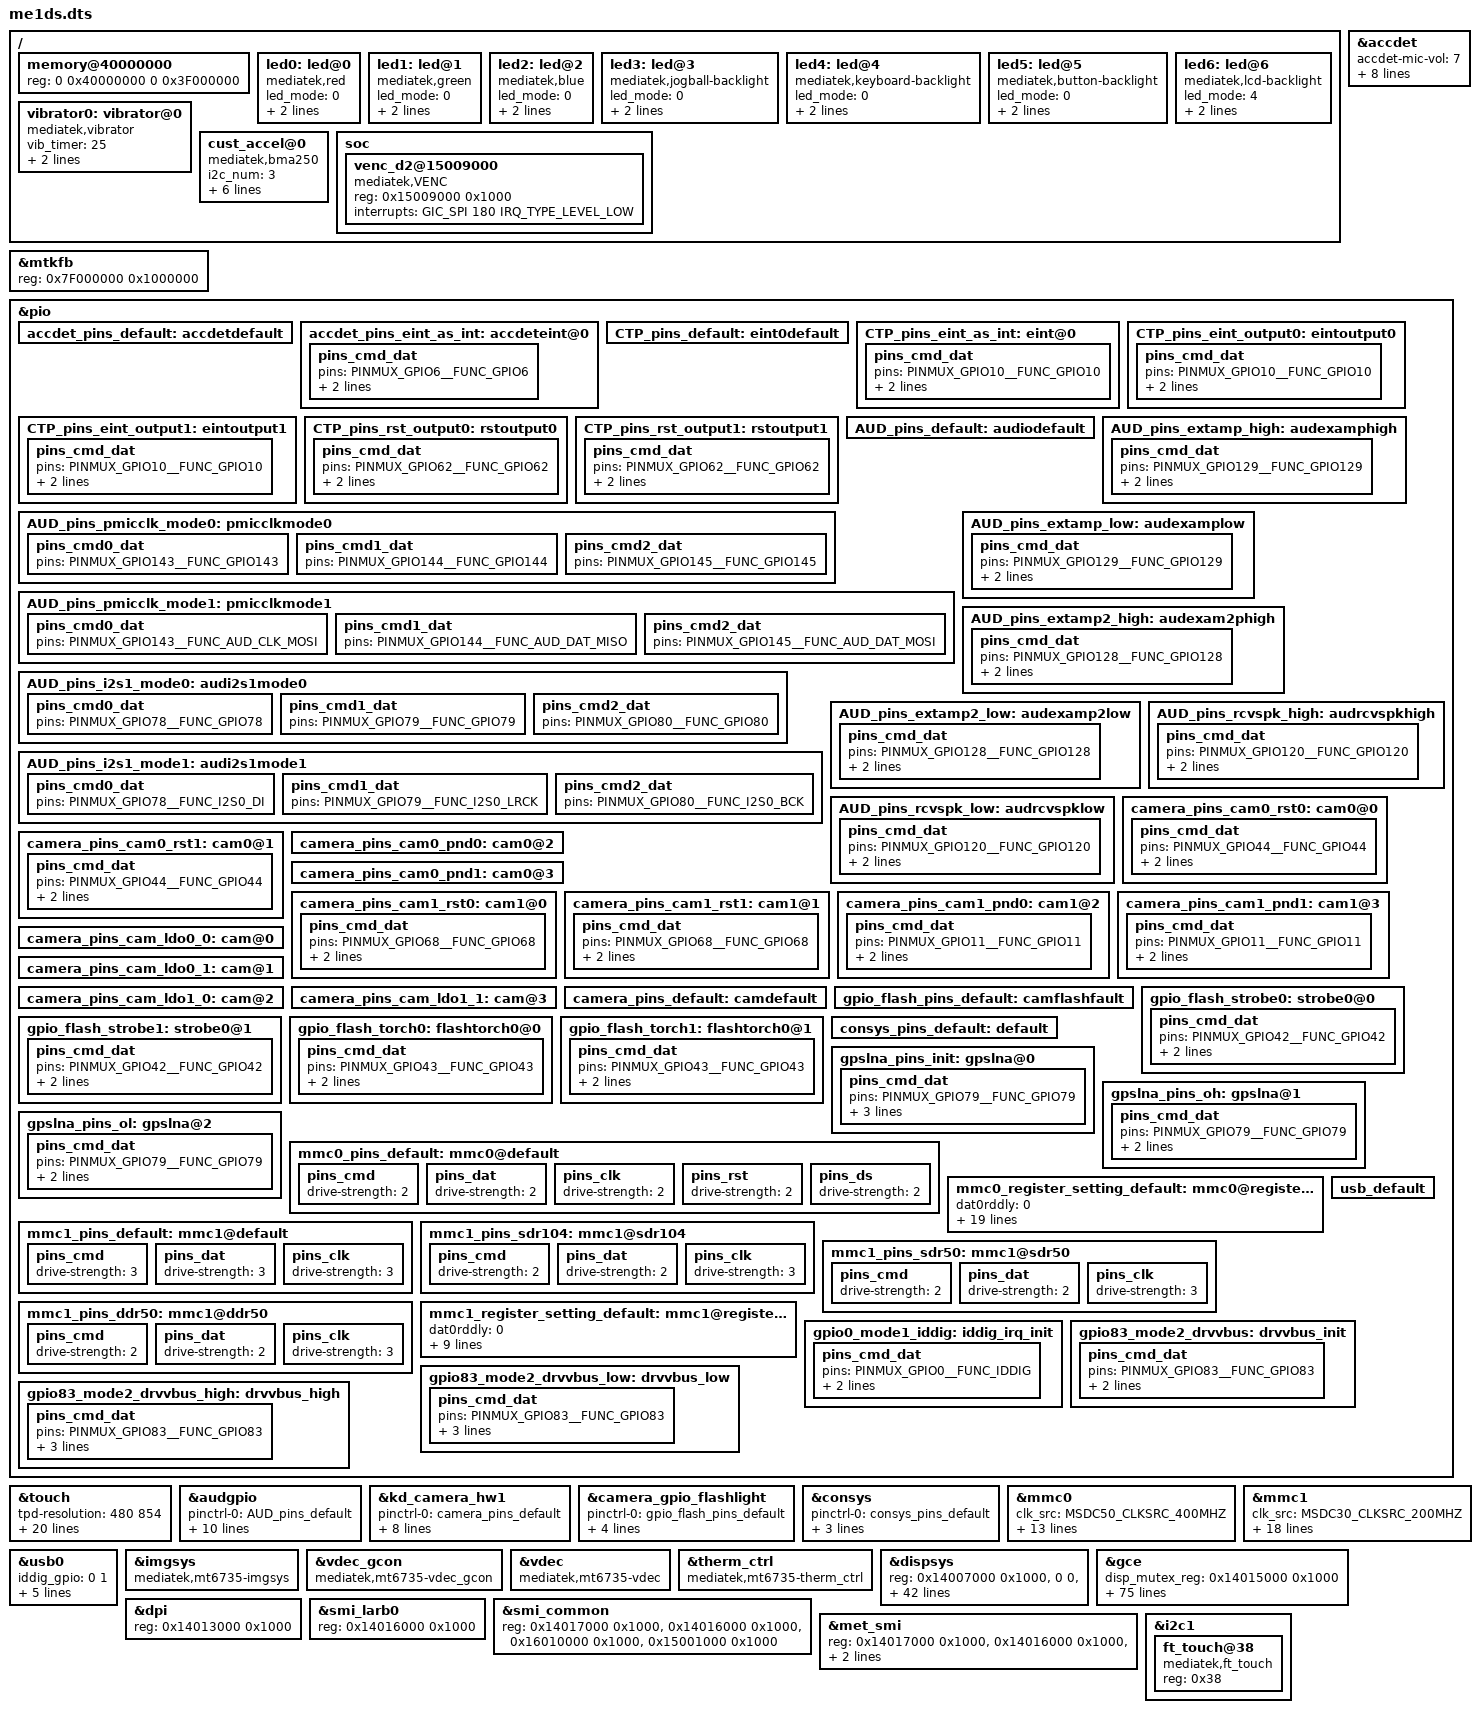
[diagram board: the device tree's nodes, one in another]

/dts-v1/;
/* LG K130 (me1ds, MT6735M), derived from the Coolpad CP8298_I00 board file */

#include "mt6735.dtsi"
#include "cust.dtsi"


/ {
	memory@40000000 {
		device_type = "memory";
		reg = <0 0x40000000 0 0x3F000000>;
	};

	led0:led@0 {
		compatible = "mediatek,red";
		led_mode = <0>;
		data = <1>;
		pwm_config = <0 0 0 0 0>;
	};
	led1:led@1 {
		compatible = "mediatek,green";
		led_mode = <0>;
		data = <2>;
		pwm_config = <0 0 0 0 0>;
	};
	led2:led@2 {
		compatible = "mediatek,blue";
		led_mode = <0>;
		data = <1>;
		pwm_config = <0 0 0 0 0>;
	};
	led3:led@3 {
		compatible = "mediatek,jogball-backlight";
		led_mode = <0>;
		data = <1>;
		pwm_config = <0 0 0 0 0>;
	};
	led4:led@4 {
		compatible = "mediatek,keyboard-backlight";
		led_mode = <0>;
		data = <1>;
		pwm_config = <0 0 0 0 0>;
	};
	led5:led@5 {
		compatible = "mediatek,button-backlight";
		led_mode = <0>;
		data = <1>;
		pwm_config = <0 0 0 0 0>;
	};
	led6:led@6 {
		compatible = "mediatek,lcd-backlight";
		led_mode = <4>;
		data = <1>;
		pwm_config = <0 0 0 0 0>;
	};
	vibrator0:vibrator@0 {
		compatible = "mediatek,vibrator";
		vib_timer = <25>;
		vib_limit = <9>;
		vib_vol= <5>;
	};



 /* sensor standardization */
		cust_accel@0 {
		compatible = "mediatek,bma250";
		i2c_num	= <3>;
		i2c_addr = <0x10 0 0 0>;
		direction = <5>;
		power_id = <0xffff>;
		power_vol = <0>;
		firlen = <0>;
		is_batch_supported = <0>;
		};








};


&mtkfb {
	reg = <0x7F000000 0x1000000>;
};




&accdet {
		accdet-mic-vol = <7>;
		headset-mode-setting = <0x500 0x200 1 0x1F0 0x800 0x800 0x20>;
		accdet-plugout-debounce = <20>;
		/*1:ACC mode, 2:low cost without in bias, 6:low cost with in bias*/
		accdet-mic-mode = <6>;
		/*0--MD_MAX--UP_MAX--DW_MAX*/
		headset-three-key-threshold = <0 80 192 500>;
		/*0--MD_MAX--VOICE_MAX--UP_MAX--DW_MAX*/
		headset-four-key-threshold = <0 58 121 192 450>;
};
/* ACCDET GPIO start*/
&pio {
	accdet_pins_default: accdetdefault {
	};
	accdet_pins_eint_as_int: accdeteint@0 {
		pins_cmd_dat {
			pins = <PINMUX_GPIO6__FUNC_GPIO6>;
			slew-rate = <0>;
			bias-disable;
		};
	};
};

&accdet {
		accdet-mic-vol = <7>;
		headset-mode-setting = <0x500 0x500 1 0x1F0 0x800 0x800 0x20>;
		accdet-plugout-debounce = <20>;
		/*1:ACC mode, 2:low cost without in bias, 6:low cost with in bias*/
		accdet-mic-mode = <1>;
		/*0--MD_MAX--UP_MAX--DW_MAX*/
		headset-three-key-threshold = <0 80 192 500>;
		/*0--MD_MAX--VOICE_MAX--UP_MAX--DW_MAX*/
		headset-four-key-threshold = <0 58 121 192 450>;
		pinctrl-names = "default", "state_eint_as_int";
		pinctrl-0 = <&accdet_pins_default>;
		pinctrl-1 = <&accdet_pins_eint_as_int>;
		status = "okay";
};
/* ACCDET GPIO end */
&touch {
	tpd-resolution = <480 854>;
	use-tpd-button = <0>;
	tpd-key-num = <3>;
	tpd-key-local= <580 172 158 0>;
	tpd-key-dim-local = <60 850 50 30 180 850 50 30 300 850 50 30 420 850 50 30>;
	tpd-max-touch-num = <5>;
	tpd-filter-enable = <0>;
	tpd-filter-pixel-density = <124>;
	tpd-filter-custom-prameters = <0 0 0 0 0 0 0 0 0 0 0 0>;
	tpd-filter-custom-speed = <0 0 0>;
	pinctrl-names = "default", "state_eint_as_int", "state_eint_output0", "state_eint_output1",
		"state_rst_output0", "state_rst_output1";
	pinctrl-0 = <&CTP_pins_default>;
	pinctrl-1 = <&CTP_pins_eint_as_int>;
	pinctrl-2 = <&CTP_pins_eint_output0>;
	pinctrl-3 = <&CTP_pins_eint_output1>;
	pinctrl-4 = <&CTP_pins_rst_output0>;
	pinctrl-5 = <&CTP_pins_rst_output1>;
	interrupt-parent = <&eintc>;
	interrupts = <10 IRQ_TYPE_EDGE_FALLING>;
	debounce = <10 0>;
	status = "okay";
};
&pio {
	CTP_pins_default: eint0default {
	};
	CTP_pins_eint_as_int: eint@0 {
		pins_cmd_dat {
			pins = <PINMUX_GPIO10__FUNC_GPIO10>;
			slew-rate = <0>;
			bias-disable;
		};
	};
	CTP_pins_eint_output0: eintoutput0 {
		pins_cmd_dat {
			pins = <PINMUX_GPIO10__FUNC_GPIO10>;
			slew-rate = <1>;
			output-low;
		};
	};
	CTP_pins_eint_output1: eintoutput1 {
		pins_cmd_dat {
			pins = <PINMUX_GPIO10__FUNC_GPIO10>;
			slew-rate = <1>;
			output-high;
		};
	};
	CTP_pins_rst_output0: rstoutput0 {
		pins_cmd_dat {
			pins = <PINMUX_GPIO62__FUNC_GPIO62>;
			slew-rate = <1>;
			output-low;
		};
	};
	CTP_pins_rst_output1: rstoutput1 {
		pins_cmd_dat {
			pins = <PINMUX_GPIO62__FUNC_GPIO62>;
			slew-rate = <1>;
			output-high;
		};
	};
};
/* TOUCH end */
/* AUDIO GPIO standardization */
&audgpio {
	pinctrl-names = "default", "audpmicclk-mode0", "audpmicclk-mode1", "audi2s1-mode0", "audi2s1-mode1", "extamp-pullhigh", "extamp-pulllow", "extamp2-pullhigh", "extamp2-pulllow", "rcvspk-pullhigh", "rcvspk-pulllow";
	pinctrl-0 = <&AUD_pins_default>;
	pinctrl-1 = <&AUD_pins_pmicclk_mode0>;
	pinctrl-2 = <&AUD_pins_pmicclk_mode1>;
	pinctrl-3 = <&AUD_pins_i2s1_mode0>;
	pinctrl-4 = <&AUD_pins_i2s1_mode1>;
	pinctrl-5 = <&AUD_pins_extamp_high>;
	pinctrl-6 = <&AUD_pins_extamp_low>;
	pinctrl-7 = <&AUD_pins_extamp2_high>;
	pinctrl-8 = <&AUD_pins_extamp2_low>;
	pinctrl-9 = <&AUD_pins_rcvspk_high>;
	pinctrl-10 = <&AUD_pins_rcvspk_low>;
	status = "okay";
};
&pio {
	AUD_pins_default: audiodefault {
	};
	AUD_pins_pmicclk_mode0: pmicclkmode0 {
		pins_cmd0_dat {
			pins = <PINMUX_GPIO143__FUNC_GPIO143>;
		};
		pins_cmd1_dat {
			pins = <PINMUX_GPIO144__FUNC_GPIO144>;
		};
		pins_cmd2_dat {
			pins = <PINMUX_GPIO145__FUNC_GPIO145>;
		};
	};
	AUD_pins_pmicclk_mode1: pmicclkmode1 {
		pins_cmd0_dat {
			pins = <PINMUX_GPIO143__FUNC_AUD_CLK_MOSI>;
		};
		pins_cmd1_dat {
			pins = <PINMUX_GPIO144__FUNC_AUD_DAT_MISO>;
		};
		pins_cmd2_dat {
			pins = <PINMUX_GPIO145__FUNC_AUD_DAT_MOSI>;
		};
	};
	AUD_pins_i2s1_mode0: audi2s1mode0 {
		pins_cmd0_dat {
			pins = <PINMUX_GPIO78__FUNC_GPIO78>;
		};
		pins_cmd1_dat {
			pins = <PINMUX_GPIO79__FUNC_GPIO79>;
		};
		pins_cmd2_dat {
			pins = <PINMUX_GPIO80__FUNC_GPIO80>;
		};
	};
	AUD_pins_i2s1_mode1: audi2s1mode1 {
		pins_cmd0_dat {
			pins = <PINMUX_GPIO78__FUNC_I2S0_DI>;
		};
		pins_cmd1_dat {
			pins = <PINMUX_GPIO79__FUNC_I2S0_LRCK>;
		};
		pins_cmd2_dat {
			pins = <PINMUX_GPIO80__FUNC_I2S0_BCK>;
		};
	};
	AUD_pins_extamp_high: audexamphigh {
		pins_cmd_dat {
			pins = <PINMUX_GPIO129__FUNC_GPIO129>;
				slew-rate = <1>;
				output-high;
		};
	};
	AUD_pins_extamp_low: audexamplow {
		pins_cmd_dat {
			pins = <PINMUX_GPIO129__FUNC_GPIO129>;
				slew-rate = <1>;
				output-low;
		};
	};
	AUD_pins_extamp2_high: audexam2phigh {
		pins_cmd_dat {
			pins = <PINMUX_GPIO128__FUNC_GPIO128>;
				slew-rate = <1>;
				output-high;
		};
	};
	AUD_pins_extamp2_low: audexamp2low {
		pins_cmd_dat {
			pins = <PINMUX_GPIO128__FUNC_GPIO128>;
				slew-rate = <1>;
				output-low;
		};
	};
	AUD_pins_rcvspk_high: audrcvspkhigh {
		pins_cmd_dat {
			pins = <PINMUX_GPIO120__FUNC_GPIO120>;
				slew-rate = <1>;
				output-high;
		};
	};
	AUD_pins_rcvspk_low: audrcvspklow {
		pins_cmd_dat {
			pins = <PINMUX_GPIO120__FUNC_GPIO120>;
				slew-rate = <1>;
				output-low;
		};
	};
};
/* AUDIO end */
/* CAMERA GPIO standardization */
&pio {
	camera_pins_cam0_rst0: cam0@0 {
		pins_cmd_dat {
			pins = <PINMUX_GPIO44__FUNC_GPIO44>;/*GPIO_CAMERA_CMRST_PIN*/
			slew-rate = <1>; /*direction 0:in, 1:out*/
			output-low;/*direction out used only. output_low or high*/
		};
	};
	camera_pins_cam0_rst1: cam0@1 {
		pins_cmd_dat {
			pins = <PINMUX_GPIO44__FUNC_GPIO44>;/*GPIO_CAMERA_CMRST_PIN*/
			slew-rate = <1>;
			output-high;
		};
	};
	camera_pins_cam0_pnd0: cam0@2 {
		/* not wired on the K130 */
	};
	camera_pins_cam0_pnd1: cam0@3 {
		/* not wired on the K130 */
	};
	camera_pins_cam1_rst0: cam1@0 {
		pins_cmd_dat {
			pins = <PINMUX_GPIO68__FUNC_GPIO68>;/*GPIO_CAMERA_CMRST1_PIN*/
			slew-rate = <1>; /*direction 0:in, 1:out*/
			output-low;/*direction out used only. output_low or high*/
		};
	};
	camera_pins_cam1_rst1: cam1@1 {
		pins_cmd_dat {
			pins = <PINMUX_GPIO68__FUNC_GPIO68>;/*GPIO_CAMERA_CMRST1_PIN*/
			slew-rate = <1>;
			output-high;
		};
	};
	camera_pins_cam1_pnd0: cam1@2 {
		pins_cmd_dat {
			pins = <PINMUX_GPIO11__FUNC_GPIO11>;/*GPIO_CAMERA_CMPDN1_PIN*/
			slew-rate = <1>;
			output-low;
		};
	};
	camera_pins_cam1_pnd1: cam1@3 {
		pins_cmd_dat {
			pins = <PINMUX_GPIO11__FUNC_GPIO11>;/*GPIO_CAMERA_CMPDN1_PIN*/
			slew-rate = <1>;
			output-high;
		};
	};
	camera_pins_cam_ldo0_0: cam@0 {
		/* not wired on the K130 */
	};
	camera_pins_cam_ldo0_1: cam@1 {
		/* not wired on the K130 */
	};
	camera_pins_cam_ldo1_0: cam@2 {
		/* not wired on the K130 */
	};
	camera_pins_cam_ldo1_1: cam@3 {
		/* not wired on the K130 */
	};
	camera_pins_default: camdefault {

	};
};

&kd_camera_hw1 {
	pinctrl-names = "default", "cam0_pnd0", "cam0_pnd1", "cam1_pnd0", "cam1_pnd1",
	"cam_ldo0_0", "cam_ldo0_1", "cam_ldo1_0", "cam_ldo1_1";
	pinctrl-0 = <&camera_pins_default>;
	pinctrl-1 = <&camera_pins_cam0_pnd0>;
	pinctrl-2 = <&camera_pins_cam0_pnd1>;
	pinctrl-3 = <&camera_pins_cam1_pnd0>;
	pinctrl-4= <&camera_pins_cam1_pnd1>;
	pinctrl-5 = <&camera_pins_cam_ldo0_0>;
	pinctrl-6 = <&camera_pins_cam_ldo0_1>;
	pinctrl-7 = <&camera_pins_cam_ldo1_0>;
	pinctrl-8 = <&camera_pins_cam_ldo1_1>;
	status = "okay";

};
/* CAMERA GPIO end */

/* CAMERA FLASH GPIO standardization */
&pio {
	gpio_flash_pins_default: camflashfault {
	};
	gpio_flash_strobe0: strobe0@0 {
		pins_cmd_dat {
			pins = <PINMUX_GPIO42__FUNC_GPIO42>;
			slew-rate = <1>;
			output-low;
		};
	};
	gpio_flash_strobe1: strobe0@1 {
		pins_cmd_dat {
			pins = <PINMUX_GPIO42__FUNC_GPIO42>;
			slew-rate = <1>;
			output-high;
		};
	};
	gpio_flash_torch0: flashtorch0@0 {
		pins_cmd_dat {
			pins = <PINMUX_GPIO43__FUNC_GPIO43>;
			slew-rate = <1>;
			output-low;
		};
	};
	gpio_flash_torch1: flashtorch0@1 {
		pins_cmd_dat {
			pins = <PINMUX_GPIO43__FUNC_GPIO43>;
			slew-rate = <1>;
			output-high;
		};
	};
};

&camera_gpio_flashlight {
	pinctrl-names = "default", "flash_strobe0", "flash_strobe1", "flash_torch0", "flash_torch1";
	pinctrl-0 = <&gpio_flash_pins_default>;
	pinctrl-1 = <&gpio_flash_strobe0>;
	pinctrl-2 = <&gpio_flash_strobe1>;
	pinctrl-3 = <&gpio_flash_torch0>;
	pinctrl-4 = <&gpio_flash_torch1>;
	status = "okay";
};
/* CAMERA FLASH GPIO end*/

/* CONSYS GPIO standardization */
&pio {
	consys_pins_default: default {

	};

	gpslna_pins_init: gpslna@0 {

	    pins_cmd_dat {
			pins = <PINMUX_GPIO79__FUNC_GPIO79>;
			slew-rate = <0>;
			bias-disable;
			output-low;
		};
	};

	gpslna_pins_oh: gpslna@1 {

	    pins_cmd_dat {
			pins = <PINMUX_GPIO79__FUNC_GPIO79>;
			slew-rate = <1>;
			output-high;
		};
	};

	gpslna_pins_ol: gpslna@2 {

	    pins_cmd_dat {
			pins = <PINMUX_GPIO79__FUNC_GPIO79>;
			slew-rate = <1>;
			output-low;
		};
	};

};

&consys {
	pinctrl-names = "default", "gps_lna_state_init", "gps_lna_state_oh", "gps_lna_state_ol";
	pinctrl-0 = <&consys_pins_default>;
	pinctrl-1 = <&gpslna_pins_init>;
	pinctrl-2 = <&gpslna_pins_oh>;
	pinctrl-3 = <&gpslna_pins_ol>;
	status = "okay";

};
/* CONSYS end */

/* mmc start */
&mmc0 {
		clk_src = /bits/ 8 <MSDC50_CLKSRC_400MHZ>;
		bus-width = <8>;
		max-frequency = <200000000>;
		cap-mmc-highspeed;
		msdc-sys-suspend;
		mmc-ddr-1_8v;
		mmc-hs200-1_8v;
		mmc-hs400-1_8v;
		non-removable;
		pinctl = <&mmc0_pins_default>;
		register_setting = <&mmc0_register_setting_default>;
		host_function = /bits/ 8 <MSDC_EMMC>;
		bootable;
		status = "okay";
};

&mmc1 {
		clk_src = /bits/ 8 <MSDC30_CLKSRC_200MHZ>;
		bus-width = <4>;
		max-frequency = <200000000>;
		msdc-sys-suspend;
		cap-sd-highspeed;
		sd-uhs-sdr12;
		sd-uhs-sdr25;
		sd-uhs-sdr50;
		sd-uhs-sdr104;
		sd-uhs-ddr50;
		pinctl = <&mmc1_pins_default>;
		pinctl_sdr104 = <&mmc1_pins_sdr104>;
		pinctl_sdr50 = <&mmc1_pins_sdr50>;
		pinctl_ddr50 = <&mmc1_pins_ddr50>;
		register_setting = <&mmc1_register_setting_default>;
		host_function = /bits/ 8 <MSDC_SD>;
		cd_level = /bits/ 8 <MSDC_CD_LOW>;
		cd-gpios = <&pio 5 0>;
		status = "okay";
};

&pio {
	mmc0_pins_default: mmc0@default {
			pins_cmd {
				drive-strength = /bits/ 8 <2>;
			};
			pins_dat {
				drive-strength = /bits/ 8 <2>;
			};
			pins_clk {
				drive-strength = /bits/ 8 <2>;
			};
			pins_rst {
				drive-strength = /bits/ 8 <2>;
			};
			pins_ds {
				drive-strength = /bits/ 8 <2>;
			};
	};

	mmc0_register_setting_default: mmc0@register_default {
		dat0rddly      = /bits/ 8 <0>;
		dat1rddly      = /bits/ 8 <0>;
		dat2rddly      = /bits/ 8 <0>;
		dat3rddly      = /bits/ 8 <0>;
		dat4rddly      = /bits/ 8 <0>;
		dat5rddly      = /bits/ 8 <0>;
		dat6rddly      = /bits/ 8 <0>;
		dat7rddly      = /bits/ 8 <0>;
		datwrddly      = /bits/ 8 <0>;
		cmdrrddly      = /bits/ 8 <0>;
		cmdrddly       = /bits/ 8 <0>;
		cmd_edge = /bits/ 8 <MSDC_SMPL_FALLING>;
		rdata_edge = /bits/ 8 <MSDC_SMPL_FALLING>;
		wdata_edge = /bits/ 8 <MSDC_SMPL_FALLING>;

		ett-hs200-cells = <12>;
		ett-hs200-default = <OFFSET_MSDC_PATCH_BIT0	MSDC_PB0_INT_DAT_LATCH_CK_SEL 0x0
			OFFSET_MSDC_PATCH_BIT0	MSDC_PB0_CKGEN_MSDC_DLY_SEL   0x0
			OFFSET_MSDC_PATCH_BIT1	MSDC_PB1_CMD_RSP_TA_CNTR      0x1
			OFFSET_MSDC_IOCON		MSDC_IOCON_RSPL               0x0
			OFFSET_MSDC_PAD_TUNE0	MSDC_PAD_TUNE0_CMDRDLY        0x7
			OFFSET_MSDC_PAD_TUNE0	MSDC_PAD_TUNE0_CMDRRDLY       0xb
			OFFSET_MSDC_PATCH_BIT1		MSDC_PB1_WRDAT_CRCS_TA_CNTR   0x1
			OFFSET_MSDC_PAD_TUNE0	MSDC_PAD_TUNE0_DATWRDLY       0xb
			OFFSET_MSDC_IOCON			MSDC_IOCON_W_D0SPL            0x0
			OFFSET_MSDC_DAT_RDDLY0		MSDC_DAT_RDDLY0_D0            0x7
			OFFSET_MSDC_PAD_TUNE0	MSDC_PAD_TUNE0_DATRRDLY       0x9
			OFFSET_MSDC_IOCON		MSDC_IOCON_R_D_SMPL           0x0>;

		ett-hs400-cells = <8>;
		ett-hs400-default = <OFFSET_MSDC_PATCH_BIT0	MSDC_PB0_INT_DAT_LATCH_CK_SEL	0x0
			OFFSET_MSDC_PATCH_BIT0		MSDC_PB0_CKGEN_MSDC_DLY_SEL		0x0
			OFFSET_EMMC50_PAD_DS_TUNE	MSDC_EMMC50_PAD_DS_TUNE_DLY1	0x2
			OFFSET_EMMC50_PAD_DS_TUNE	MSDC_EMMC50_PAD_DS_TUNE_DLY3	0x10
			OFFSET_MSDC_PATCH_BIT1			MSDC_PB1_CMD_RSP_TA_CNTR	0x1
			OFFSET_MSDC_IOCON		MSDC_IOCON_RSPL				0x0
			OFFSET_MSDC_PAD_TUNE0			MSDC_PAD_TUNE0_CMDRDLY		0x6
			OFFSET_MSDC_PAD_TUNE0		MSDC_PAD_TUNE0_CMDRRDLY		0x6>;
	};

	mmc1_pins_default: mmc1@default {
			pins_cmd {
				drive-strength = /bits/ 8 <3>;
			};
			pins_dat {
				drive-strength = /bits/ 8 <3>;
			};
			pins_clk {
				drive-strength = /bits/ 8 <3>;
			};
	};

	mmc1_pins_sdr104: mmc1@sdr104 {
			pins_cmd {
				drive-strength = /bits/ 8 <2>;
			};
			pins_dat {
				drive-strength = /bits/ 8 <2>;
			};
			pins_clk {
				drive-strength = /bits/ 8 <3>;
			};
	};

	mmc1_pins_sdr50: mmc1@sdr50 {
			pins_cmd {
				drive-strength = /bits/ 8 <2>;
			};
			pins_dat {
				drive-strength = /bits/ 8 <2>;
			};
			pins_clk {
				drive-strength = /bits/ 8 <3>;
			};
	};

	mmc1_pins_ddr50: mmc1@ddr50 {
			pins_cmd {
				drive-strength = /bits/ 8 <2>;
			};
			pins_dat {
				drive-strength = /bits/ 8 <2>;
			};
			pins_clk {
				drive-strength = /bits/ 8 <3>;
			};
	};

	mmc1_register_setting_default: mmc1@register_default {
				dat0rddly      = /bits/ 8 <0>;
				dat1rddly      = /bits/ 8 <0>;
				dat2rddly      = /bits/ 8 <0>;
				dat3rddly      = /bits/ 8 <0>;
				datwrddly      = /bits/ 8 <0>;
				cmdrrddly      = /bits/ 8 <0>;
				cmdrddly       = /bits/ 8 <0>;
				cmd_edge = /bits/ 8 <MSDC_SMPL_FALLING>;
				rdata_edge = /bits/ 8 <MSDC_SMPL_FALLING>;
				wdata_edge = /bits/ 8 <MSDC_SMPL_FALLING>;
	};
};
/* mmc end */




/* NFC end */

/* USB GPIO Kernal Standardization start */
&pio {
	usb_default: usb_default {
	};

	gpio0_mode1_iddig: iddig_irq_init {
		pins_cmd_dat {
			pins = <PINMUX_GPIO0__FUNC_IDDIG>;
			slew-rate = <0>;
			bias-pull-up = <00>;
		};
	};

	gpio83_mode2_drvvbus: drvvbus_init {
		pins_cmd_dat {
			pins = <PINMUX_GPIO83__FUNC_GPIO83>;
			slew-rate = <1>;
			bias-pull-down = <00>;
		};
	};

	gpio83_mode2_drvvbus_low: drvvbus_low {
		pins_cmd_dat {
			pins = <PINMUX_GPIO83__FUNC_GPIO83>;
			slew-rate = <1>;
			output-low;
			bias-pull-down = <00>;
		};
	};

	gpio83_mode2_drvvbus_high: drvvbus_high {
		pins_cmd_dat {
			pins = <PINMUX_GPIO83__FUNC_GPIO83>;
			slew-rate = <1>;
			output-high;
			bias-pull-down = <00>;
		};
	};
};

&usb0 {
	iddig_gpio = <0 1>;
	pinctrl-names = "usb_default", "iddig_irq_init", "drvvbus_init", "drvvbus_low", "drvvbus_high";
	pinctrl-0 = <&usb_default>;
	pinctrl-1 = <&gpio0_mode1_iddig>;
	pinctrl-2 = <&gpio83_mode2_drvvbus>;
	pinctrl-3 = <&gpio83_mode2_drvvbus_low>;
	pinctrl-4 = <&gpio83_mode2_drvvbus_high>;
	status = "okay";
};
/* USB GPIO Kernal Standardization end */



/*
 * The MT6735M (D2) clkmgr, thermal and video codec drivers look nodes up
 * by MediaTek's older upper-case names (LG's mt6735m.dtsi). Give the
 * matching mt6735.dtsi nodes those names too; the D2 encoder lives at
 * 0x15009000, not the D1 VENC block.
 */
&imgsys {
	compatible = "mediatek,mt6735-imgsys", "mediatek,IMGSYS";
};

&vdec_gcon {
	compatible = "mediatek,mt6735-vdec_gcon", "mediatek,VDEC_GCON";
};

&vdec {
	compatible = "mediatek,mt6735-vdec", "mediatek,VDEC_FULL_TOP";
};

&therm_ctrl {
	compatible = "mediatek,mt6735-therm_ctrl", "mediatek,THERM_CTRL";
};

/ {
	soc {
		venc_d2@15009000 {
			compatible = "mediatek,VENC";
			reg = <0x15009000 0x1000>;
			interrupts = <GIC_SPI 180 IRQ_TYPE_LEVEL_LOW>;
		};
	};
};

/*
 * MT6735M multimedia map. The D2 display blocks after OVL0 sit one 4 KiB
 * slot higher than on MT6735, the IRQs and GCE events are numbered
 * differently, and there is no VENC larb3. Values from MediaTek's
 * mt6735m.dtsi, matching LG's K130 DISPSYS node.
 */
&dispsys {
	reg = <0x14007000 0x1000>,  /*DISP_OVL0      */
	<0 0>,		    /*DISP_OVL1      */
	<0x14009000 0x1000>,  /*DISP_RDMA0     */
	<0 0>,  /*DISP_RDMA1     */
	<0x1400B000 0x1000>,  /*DISP_WDMA0     */
	<0x1400C000 0x1000>,  /*DISP_COLOR     */
	<0x1400D000 0x1000>,  /*DISP_CCORR     */
	<0x1400E000 0x1000>,  /*DISP_AAL       */
	<0x1400F000 0x1000>,  /*DISP_GAMMA     */
	<0x14010000 0x1000>,  /*DISP_DITHER    */
	<0 0>,		    /*DISP_UFOE      */
	<0x1100E000 0x1000>,  /*DISP_PWM       */
	<0 0>,		    /*DISP_WDMA1     */
	<0x14015000 0x1000>,  /*DISP_MUTEX     */
	<0x14012000 0x1000>,  /*DISP_DSI0      */
	<0x14013000 0x1000>,  /*DISP_DPI0      */
	<0x14000000 0x1000>,  /*DISP_CONFIG    */
	<0x14016000 0x1000>,  /*DISP_SMI_LARB0 */
	<0x14017000 0x1000>,  /*DISP_SMI_COMMOM*/
	<0x14018000 0x1000>,  /*MIPITX0,real chip would use this:<0x14017000 0x1000>;*/
	<0x10206000 0x1000>,  /*DISP_CONFIG2*/
	<0x10210000 0x1000>,  /*DISP_CONFIG3*/
	<0x10211A70 0x000C>,  /*DISP_DPI_IO_DRIVING1 */
	<0x10211974 0x000C>,  /*DISP_DPI_IO_DRIVING2 */
	<0x10211B70 0x000C>,  /*DISP_DPI_IO_DRIVING3 */
	<0x10206044 0x000C>,  /*DISP_DPI_EFUSE */
	<0x10206514 0x000C>,  /*DISP_DPI_EFUSE_PERMISSION */
	<0x10206558 0x000C>,  /*DISP_DPI_EFUSE_KEY */
	<0x102100A0 0x1000>,  /*DISP_TVDPLL_CFG6 */
	<0x10209270 0x1000>,  /*DISP_TVDPLL_CON0 */
	<0x10209274 0x1000>,  /*DISP_TVDPLL_CON1 */
	<0 0>,		    /*DISP_OD      */
	<0x10209000 0x1000>;
	interrupts = <GIC_SPI 193 IRQ_TYPE_LEVEL_LOW>, /*DISP_OVL0 */
	<GIC_SPI 0 IRQ_TYPE_LEVEL_LOW>,   /*DISP_OVL1 */
	<GIC_SPI 195 IRQ_TYPE_LEVEL_LOW>, /*DISP_RDMA0 */
	<GIC_SPI 0 IRQ_TYPE_LEVEL_LOW>, /*DISP_RDMA1 */
	<GIC_SPI 197 IRQ_TYPE_LEVEL_LOW>, /*DISP_WDMA0 */
	<GIC_SPI 198 IRQ_TYPE_LEVEL_LOW>, /*DISP_COLOR */
	<GIC_SPI 199 IRQ_TYPE_LEVEL_LOW>, /*DISP_CCORR */
	<GIC_SPI 200 IRQ_TYPE_LEVEL_LOW>, /*DISP_AAL */
	<GIC_SPI 201 IRQ_TYPE_LEVEL_LOW>, /*DISP_GAMMA */
	<GIC_SPI 202 IRQ_TYPE_LEVEL_LOW>, /*DISP_DITHER */
	<GIC_SPI 0 IRQ_TYPE_LEVEL_LOW>,   /*DISP_UFOE */
	<GIC_SPI 117 IRQ_TYPE_LEVEL_LOW>, /*DISP_PWM */
	<GIC_SPI 0 IRQ_TYPE_LEVEL_LOW>,   /*DISP_WDMA1 */
	<GIC_SPI 186 IRQ_TYPE_LEVEL_LOW>, /*DISP_MUTEX */
	<GIC_SPI 204 IRQ_TYPE_LEVEL_LOW>, /*DISP_DSI0 */
	<GIC_SPI 205 IRQ_TYPE_LEVEL_LOW>, /*DISP_DPI0 */
	<GIC_SPI 206 IRQ_TYPE_LEVEL_LOW>, /*DISP_CONFIG, 0 means no IRQ*/
	<GIC_SPI 176 IRQ_TYPE_LEVEL_LOW>, /*DISP_SMI_LARB0 */
	<GIC_SPI 0 IRQ_TYPE_LEVEL_LOW>,   /*DISP_SMI_COMMOM*/
	<GIC_SPI 0 IRQ_TYPE_LEVEL_LOW>,   /*MIPITX0 */
	<GIC_SPI 0 IRQ_TYPE_LEVEL_LOW>,   /*DISP_CONFIG2*/
	<GIC_SPI 0 IRQ_TYPE_LEVEL_LOW>,   /*DISP_CONFIG3*/
	<GIC_SPI 0 IRQ_TYPE_LEVEL_LOW>,   /*DISP_DPI_IO_DRIVING */
	<GIC_SPI 0 IRQ_TYPE_LEVEL_LOW>,   /*DISP_TVDPLL_CFG6 */
	<GIC_SPI 0 IRQ_TYPE_LEVEL_LOW>,   /*DISP_TVDPLL_CON0 */
	<GIC_SPI 0 IRQ_TYPE_LEVEL_LOW>,   /*DISP_TVDPLL_CON1 */
	<GIC_SPI 0 IRQ_TYPE_LEVEL_LOW>,   /*DISP_OD      */
	<GIC_SPI 0 IRQ_TYPE_LEVEL_LOW>;
};

&gce {
	disp_mutex_reg = <0x14015000 0x1000>;
	g3d_config_base = <0x13000000 0 0xffff0000>;
	mmsys_config_base = <0x14000000 1 0xffff0000>;
	disp_dither_base = <0x14010000 2 0xffff0000>;
	mm_na_base = <0x14020000 3 0xffff0000>;
	imgsys_base = <0x15000000 4 0xffff0000>;
	vdec_gcon_base = <0x16000000 5 0xffff0000>;
	venc_gcon_base = <0x17000000 6 0xffff0000>;
	conn_peri_base = <0x18000000 7 0xffff0000>;
	topckgen_base = <0x10000000 8 0xffff0000>;
	kp_base = <0x10010000 9 0xffff0000>;
	scp_sram_base = <0x10020000 10 0xffff0000>;
	infra_na3_base = <0x10030000 11 0xffff0000>;
	infra_na4_base = <0x10040000 12 0xffff0000>;
	scp_base = <0x10050000 13 0xffff0000>;
	mcucfg_base = <0x10200000 14 0xffff0000>;
	gcpu_base = <0x10210000 15 0xffff0000>;
	usb0_base = <0x11200000 16 0xffff0000>;
	usb_sif_base = <0x11210000 17 0xffff0000>;
	audio_base = <0x11220000 18 0xffff0000>;
	msdc0_base = <0x11230000 19 0xffff0000>;
	msdc1_base = <0x11240000 20 0xffff0000>;
	msdc2_base = <0x11250000 21 0xffff0000>;
	msdc3_base = <0x11260000 22 0xffff0000>;
	pwm_sw_base = <0x1100E000 99 0xfffff000>;
	mdp_rdma0_sof = <0>;
	mdp_rsz0_sof = <1>;
	mdp_rsz1_sof = <2>;
	mdp_tdshp_sof = <3>;
	mdp_wdma_sof = <4>;
	mdp_wrot_sof = <5>;
	disp_ovl0_sof = <6>;
	disp_rdma0_sof = <8>;
	disp_rdma1_sof = <9>;
	disp_wdma0_sof = <10>;
	disp_ccorr_sof = <11>;
	disp_color_sof = <12>;
	disp_aal_sof = <13>;
	disp_gamma_sof = <14>;
	disp_dither_sof = <15>;
	disp_pwm0_sof = <17>;
	mdp_rdma0_frame_done = <18>;
	mdp_rsz0_frame_done = <19>;
	mdp_rsz1_frame_done = <20>;
	mdp_tdshp_frame_done = <21>;
	mdp_wdma_frame_done = <22>;
	mdp_wrot_write_frame_done = <23>;
	mdp_wrot_read_frame_done = <24>;
	disp_ovl0_frame_done = <25>;
	disp_rdma0_frame_done = <27>;
	disp_rdma1_frame_done = <28>;
	disp_wdma0_frame_done = <29>;
	disp_ccorr_frame_done = <30>;
	disp_color_frame_done = <31>;
	disp_aal_frame_done = <32>;
	disp_gamma_frame_done = <33>;
	disp_dither_frame_done = <34>;
	disp_dpi0_frame_done = <36>;
	disp_dsi0_frame_done = <37>;
	stream_done_0 = <38>;
	stream_done_1 = <39>;
	stream_done_2 = <40>;
	stream_done_3 = <41>;
	stream_done_4 = <42>;
	stream_done_5 = <43>;
	stream_done_6 = <44>;
	stream_done_7 = <45>;
	stream_done_8 = <46>;
	stream_done_9 = <47>;
	buf_underrun_event_0 = <48>;
	buf_underrun_event_1 = <49>;
	dsi0_te_event = <50>;
	isp_frame_done_p2_1 = <66>;
	isp_frame_done_p2_0 = <67>;
	seninf_cam0_fifo_full = <73>;
	apxgpt2_count = <0x10004028>;
};

&dpi {
	reg = <0x14013000 0x1000>;
};

&smi_larb0 {
	reg = <0x14016000 0x1000>;
};

&smi_common {
	reg = <0x14017000 0x1000>,	/* SMI_COMMON_EXT */
	      <0x14016000 0x1000>,	/* LARB 0 */
	      <0x16010000 0x1000>,	/* LARB 1 */
	      <0x15001000 0x1000>;	/* LARB 2 */
};

&met_smi {
	reg = <0x14017000 0x1000>,	/* SMI_COMMON_EXT */
	      <0x14016000 0x1000>,	/* LARB 0 */
	      <0x16010000 0x1000>,	/* LARB 1 */
	      <0x15001000 0x1000>,	/* LARB 2 */
	      <0x17001000 0x1000>;	/* LARB 3 */
};

/* FocalTech FT6x36 touch controller: I2C1, address 0x38 (LG lgtp_model_config_i2c.h) */
&i2c1 {
	ft_touch@38 {
		compatible = "mediatek,ft_touch";
		reg = <0x38>;
		status = "okay";
	};
};
